# TM4C1233H6PGE register map
Vendor: Texas Instruments; File version: 11073
CPU: CM4 r1p2, little endian, no MPU, no FPU, 0x3 interrupt priority bits, 0x0 interrupts
Registers are 32-bit, read-write, no defined reset value unless marked. A register's access mark holds for its fields unless they carry their own. Offsets are from the block's base; [hi:lo] are bit positions; {n}, {i} and the like mark numbered series.

## USB0 — Register map for USB0 peripheral
Base 0x40050000; register names take the prefix USB0
0x00 FADDR 8-bit — USB Device Functional Address
  [6:0] USB_FADDR — Function Address
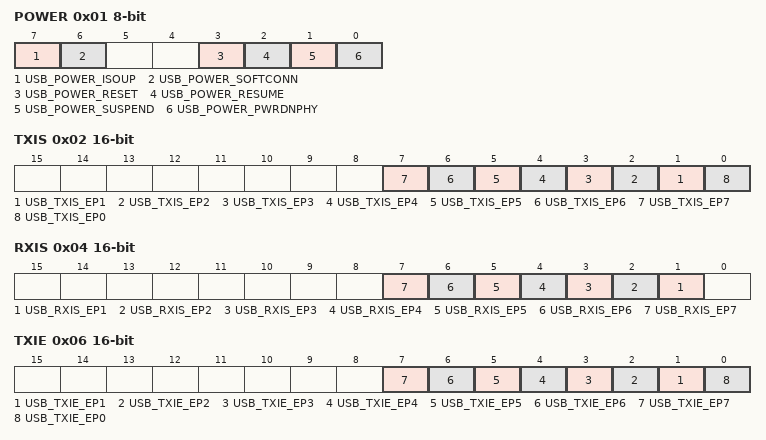
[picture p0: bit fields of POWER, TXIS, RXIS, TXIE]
0x01 POWER 8-bit — USB Power
  [7] USB_POWER_ISOUP — Isochronous Update
  [6] USB_POWER_SOFTCONN — Soft Connect/Disconnect
  [3] USB_POWER_RESET — RESET Signaling
  [2] USB_POWER_RESUME — RESUME Signaling
  [1] USB_POWER_SUSPEND — SUSPEND Mode
  [0] USB_POWER_PWRDNPHY — Power Down PHY
0x02 TXIS 16-bit — USB Transmit Interrupt Status
  [n] USB_TXIS_EP{n} (n=1..7) — TX Endpoint {n} Interrupt
  [0] USB_TXIS_EP0 — TX and RX Endpoint 0 Interrupt
0x04 RXIS 16-bit — USB Receive Interrupt Status
  [n] USB_RXIS_EP{n} (n=1..7) — RX Endpoint {n} Interrupt
0x06 TXIE 16-bit — USB Transmit Interrupt Enable
  [n] USB_TXIE_EP{n} (n=1..7) — TX Endpoint {n} Interrupt Enable
  [0] USB_TXIE_EP0 — TX and RX Endpoint 0 Interrupt Enable
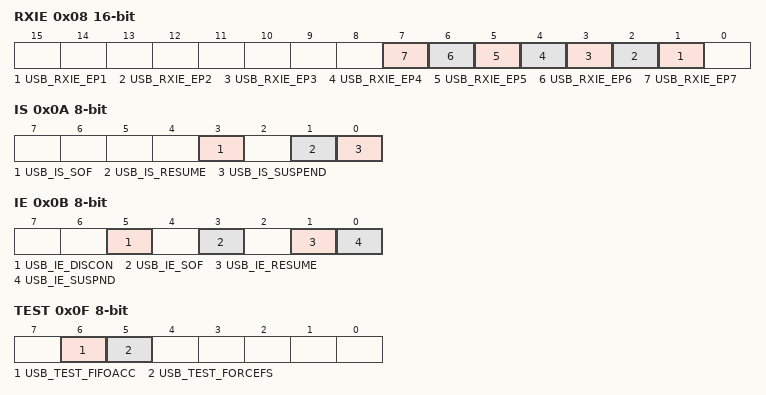
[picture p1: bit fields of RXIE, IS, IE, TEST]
0x08 RXIE 16-bit — USB Receive Interrupt Enable
  [n] USB_RXIE_EP{n} (n=1..7) — RX Endpoint {n} Interrupt Enable
0x0A IS 8-bit — USB General Interrupt Status
  [3] USB_IS_SOF — Start of Frame
  [1] USB_IS_RESUME — RESUME Signaling Detected
  [0] USB_IS_SUSPEND — SUSPEND Signaling Detected
0x0A IS 8-bit (USB0_ALT view) — USB General Interrupt Status
  [2] USB_IS_RESET — RESET Signaling Detected
0x0B IE 8-bit — USB Interrupt Enable
  [5] USB_IE_DISCON — Enable Disconnect Interrupt
  [3] USB_IE_SOF — Enable Start-of-Frame Interrupt
  [1] USB_IE_RESUME — Enable RESUME Interrupt
  [0] USB_IE_SUSPND — Enable SUSPEND Interrupt
0x0B IE 8-bit (USB0_ALT view) — USB Interrupt Enable
  [2] USB_IE_RESET — Enable RESET Interrupt
0x0C FRAME 16-bit — USB Frame Value
  [10:0] USB_FRAME — Frame Number
0x0E EPIDX 8-bit — USB Endpoint Index
  [3:0] USB_EPIDX_EPIDX — Endpoint Index
0x0F TEST 8-bit — USB Test Mode
  [6] USB_TEST_FIFOACC — FIFO Access
  [5] USB_TEST_FORCEFS — Force Full-Speed Mode
{0x20+4i} FIFO{i} (i=0..7) — USB FIFO Endpoint {i}
  [31:0] USB_FIFO{i}_EPDATA — Endpoint Data
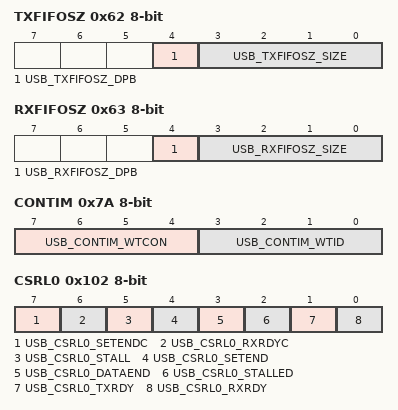
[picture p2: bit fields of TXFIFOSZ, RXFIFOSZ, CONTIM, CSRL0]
0x62 TXFIFOSZ 8-bit — USB Transmit Dynamic FIFO Sizing
  [4] USB_TXFIFOSZ_DPB — Double Packet Buffer Support
  [3:0] USB_TXFIFOSZ_SIZE — Max Packet Size
    0=8; 1=16; 2=32; 3=64; 4=128; 5=256; 6=512; 7=1024; 8=2048
0x63 RXFIFOSZ 8-bit — USB Receive Dynamic FIFO Sizing
  [4] USB_RXFIFOSZ_DPB — Double Packet Buffer Support
  [3:0] USB_RXFIFOSZ_SIZE — Max Packet Size
    0=8; 1=16; 2=32; 3=64; 4=128; 5=256; 6=512; 7=1024; 8=2048
0x64 TXFIFOADD 16-bit — USB Transmit FIFO Start Address
  [8:0] USB_TXFIFOADD_ADDR — Transmit/Receive Start Address
0x66 RXFIFOADD 16-bit — USB Receive FIFO Start Address
  [8:0] USB_RXFIFOADD_ADDR — Transmit/Receive Start Address
0x7A CONTIM 8-bit — USB Connect Timing
  [7:4] USB_CONTIM_WTCON — Connect Wait
  [3:0] USB_CONTIM_WTID — Wait ID
0x7D FSEOF 8-bit — USB Full-Speed Last Transaction to End of Frame Timing
  [7:0] USB_FSEOF_FSEOFG — Full-Speed End-of-Frame Gap
0x7E LSEOF 8-bit — USB Low-Speed Last Transaction to End of Frame Timing
  [7:0] USB_LSEOF_LSEOFG — Low-Speed End-of-Frame Gap
0x102 CSRL0 8-bit wo — USB Control and Status Endpoint 0 Low
  [7] USB_CSRL0_SETENDC — Setup End Clear
  [6] USB_CSRL0_RXRDYC — RXRDY Clear
  [5] USB_CSRL0_STALL — Send Stall
  [4] USB_CSRL0_SETEND — Setup End
  [3] USB_CSRL0_DATAEND — Data End
  [2] USB_CSRL0_STALLED — Endpoint Stalled
  [1] USB_CSRL0_TXRDY — Transmit Packet Ready
  [0] USB_CSRL0_RXRDY — Receive Packet Ready
0x103 CSRH0 8-bit wo — USB Control and Status Endpoint 0 High
  [0] USB_CSRH0_FLUSH — Flush FIFO
0x108 COUNT0 8-bit — USB Receive Byte Count Endpoint 0
  [6:0] USB_COUNT0_COUNT — FIFO Count
{0x100+0x10*i} TXMAXP{i} 16-bit (i=1..7) — USB Maximum Transmit Data Endpoint {i}
  [10:0] USB_TXMAXP{i}_MAXLOAD — Maximum Payload
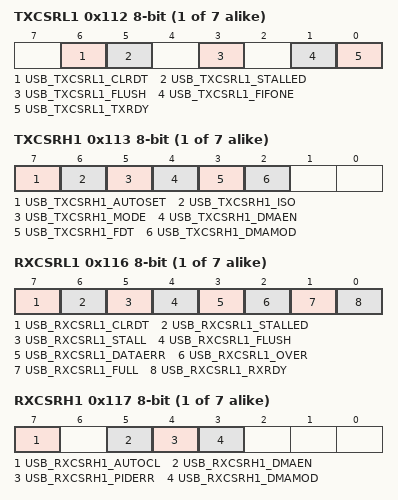
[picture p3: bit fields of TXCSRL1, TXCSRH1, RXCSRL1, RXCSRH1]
{0x102+0x10*i} TXCSRL{i} 8-bit (i=1..7) — USB Transmit Control and Status Endpoint {i} Low
  [6] USB_TXCSRL{i}_CLRDT — Clear Data Toggle
  [5] USB_TXCSRL{i}_STALLED — Endpoint Stalled
  [3] USB_TXCSRL{i}_FLUSH — Flush FIFO
  [1] USB_TXCSRL{i}_FIFONE — FIFO Not Empty
  [0] USB_TXCSRL{i}_TXRDY — Transmit Packet Ready
{0x102+0x10*i} TXCSRL{i} 8-bit (USB0_ALT view) (i=1..7) — USB Transmit Control and Status Endpoint {i} Low
  [4] USB_TXCSRL{i}_STALL — Send STALL
  [2] USB_TXCSRL{i}_UNDRN — Underrun
{0x103+0x10*i} TXCSRH{i} 8-bit (i=1..7) — USB Transmit Control and Status Endpoint {i} High
  [7] USB_TXCSRH{i}_AUTOSET — Auto Set
  [6] USB_TXCSRH{i}_ISO — Isochronous Transfers
  [5] USB_TXCSRH{i}_MODE — Mode
  [4] USB_TXCSRH{i}_DMAEN — DMA Request Enable
  [3] USB_TXCSRH{i}_FDT — Force Data Toggle
  [2] USB_TXCSRH{i}_DMAMOD — DMA Request Mode
{0x104+0x10*i} RXMAXP{i} 16-bit (i=1..7) — USB Maximum Receive Data Endpoint {i}
  [10:0] USB_RXMAXP{i}_MAXLOAD — Maximum Payload
{0x106+0x10*i} RXCSRL{i} 8-bit (i=1..7) — USB Receive Control and Status Endpoint {i} Low
  [7] USB_RXCSRL{i}_CLRDT — Clear Data Toggle
  [6] USB_RXCSRL{i}_STALLED — Endpoint Stalled
  [5] USB_RXCSRL{i}_STALL — Send STALL
  [4] USB_RXCSRL{i}_FLUSH — Flush FIFO
  [3] USB_RXCSRL{i}_DATAERR — Data Error
  [2] USB_RXCSRL{i}_OVER — Overrun
  [1] USB_RXCSRL{i}_FULL — FIFO Full
  [0] USB_RXCSRL{i}_RXRDY — Receive Packet Ready
{0x107+0x10*i} RXCSRH{i} 8-bit (i=1..7) — USB Receive Control and Status Endpoint {i} High
  [7] USB_RXCSRH{i}_AUTOCL — Auto Clear
  [5] USB_RXCSRH{i}_DMAEN — DMA Request Enable
  [4] USB_RXCSRH{i}_PIDERR — PID Error
  [3] USB_RXCSRH{i}_DMAMOD — DMA Request Mode
{0x107+0x10*i} RXCSRH{i} 8-bit (USB0_ALT view) (i=1..7) — USB Receive Control and Status Endpoint {i} High
  [6] USB_RXCSRH{i}_ISO — Isochronous Transfers
  [4] USB_RXCSRH{i}_DISNYET — Disable NYET
{0x108+0x10*i} RXCOUNT{i} 16-bit (i=1..7) — USB Receive Byte Count Endpoint {i}
  [12:0] USB_RXCOUNT{i}_COUNT — Receive Packet Count
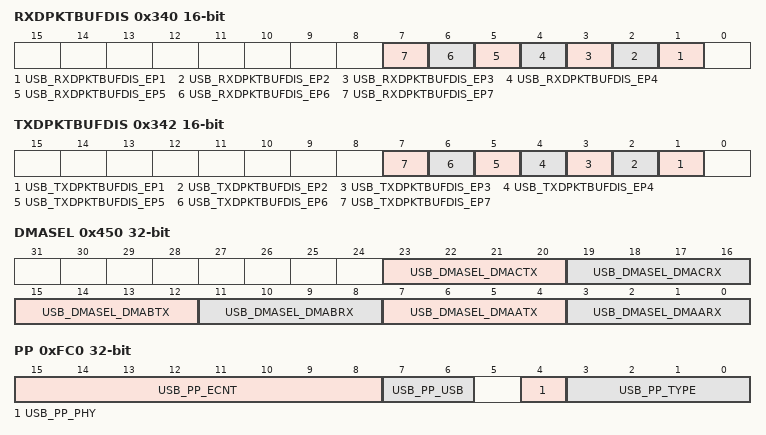
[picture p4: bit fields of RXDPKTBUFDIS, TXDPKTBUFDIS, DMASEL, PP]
0x340 RXDPKTBUFDIS 16-bit — USB Receive Double Packet Buffer Disable
  [n] USB_RXDPKTBUFDIS_EP{n} (n=1..7) — EP{n} RX Double-Packet Buffer Disable
0x342 TXDPKTBUFDIS 16-bit — USB Transmit Double Packet Buffer Disable
  [n] USB_TXDPKTBUFDIS_EP{n} (n=1..7) — EP{n} TX Double-Packet Buffer Disable
0x410 DRRIS — USB Device RESUME Raw Interrupt Status
  [0] USB_DRRIS_RESUME — RESUME Interrupt Status
0x414 DRIM — USB Device RESUME Interrupt Mask
  [0] USB_DRIM_RESUME — RESUME Interrupt Mask
0x418 DRISC wo — USB Device RESUME Interrupt Status and Clear
  [0] USB_DRISC_RESUME — RESUME Interrupt Status and Clear
0x450 DMASEL — USB DMA Select
  [23:20] USB_DMASEL_DMACTX — DMA C TX Select
  [19:16] USB_DMASEL_DMACRX — DMA C RX Select
  [15:12] USB_DMASEL_DMABTX — DMA B TX Select
  [11:8] USB_DMASEL_DMABRX — DMA B RX Select
  [7:4] USB_DMASEL_DMAATX — DMA A TX Select
  [3:0] USB_DMASEL_DMAARX — DMA A RX Select
0xFC0 PP — USB Peripheral Properties
  [15:8] USB_PP_ECNT — Endpoint Count
  [7:6] USB_PP_USB — USB Capability
    1=USB_PP_USB_DEVICE (DEVICE); 2=USB_PP_USB_HOSTDEVICE (HOST); 3=USB_PP_USB_OTG (OTG)
  [4] USB_PP_PHY — PHY Present
  [3:0] USB_PP_TYPE — Controller Type
    0=The first-generation USB controller
